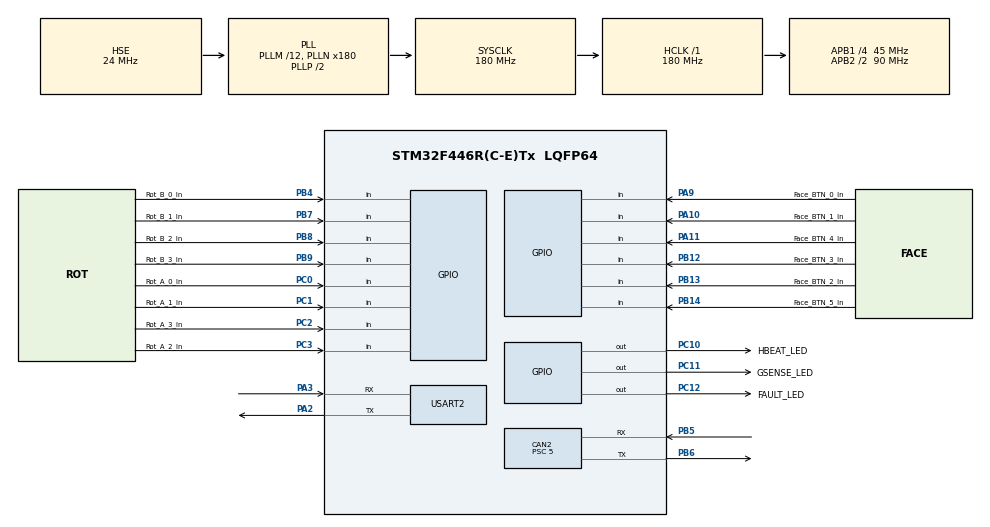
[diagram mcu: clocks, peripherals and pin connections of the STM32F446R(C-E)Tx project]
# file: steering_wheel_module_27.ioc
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CAN2.BS1=CAN_BS1_6TQ
CAN2.BS2=CAN_BS2_1TQ
CAN2.CalculateBaudRate=1125000
CAN2.CalculateTimeBit=888
CAN2.CalculateTimeQuantum=111.11111111111111
CAN2.Prescaler=5
FREERTOS.Tasks01=mainLoop,0,1024,main_task,Default,NULL,Dynamic,NULL,NULL;gcanBuffTask,0,1024,gcan_buffer_task,Default,NULL,Dynamic,NULL,NULL
FREERTOS.configENABLE_FPU=1
Mcu.Family=STM32F4
Mcu.Name=STM32F446R(C-E)Tx
Mcu.Package=LQFP64
NVIC.PriorityGroup=NVIC_PRIORITYGROUP_4
NVIC.TIM1_UP_TIM10_IRQn=true\:5\:0\:false\:false\:true\:true\:true\:true\:true
NVIC.TIM6_DAC_IRQn=true\:15\:0\:false\:false\:true\:false\:false\:true\:true
NVIC.TimeBase=TIM6_DAC_IRQn
NVIC.TimeBaseIP=TIM6
PA10.GPIO_Label=Face_BTN_1_In
PA10.Signal=GPIO_Input
PA11.GPIO_Label=Face_BTN_4_In
PA11.Signal=GPIO_Input
PA13.Signal=SYS_JTMS-SWDIO
PA14.Signal=SYS_JTCK-SWCLK
PA2.Mode=Asynchronous
PA2.Signal=USART2_TX
PA3.Mode=Asynchronous
PA3.Signal=USART2_RX
PA9.GPIO_Label=Face_BTN_0_In
PA9.Signal=GPIO_Input
PB12.GPIO_Label=Face_BTN_3_In
PB12.Signal=GPIO_Input
PB13.GPIO_Label=Face_BTN_2_In
PB13.Signal=GPIO_Input
PB14.GPIO_Label=Face_BTN_5_In
PB14.Signal=GPIO_Input
PB3.Signal=SYS_JTDO-SWO
PB4.GPIO_Label=Rot_B_0_In
PB4.Signal=GPIO_Input
PB5.Mode=CAN_Activate
PB5.Signal=CAN2_RX
PB6.Mode=CAN_Activate
PB6.Signal=CAN2_TX
PB7.GPIO_Label=Rot_B_1_In
PB7.Signal=GPIO_Input
PB8.GPIO_Label=Rot_B_2_In
PB8.Signal=GPIO_Input
PB9.GPIO_Label=Rot_B_3_In
PB9.Signal=GPIO_Input
PC0.GPIO_Label=Rot_A_0_In
PC0.Signal=GPIO_Input
PC1.GPIO_Label=Rot_A_1_In
PC1.Signal=GPIO_Input
PC10.GPIO_Label=HBEAT_LED
PC10.Signal=GPIO_Output
PC11.GPIO_Label=GSENSE_LED
PC11.Signal=GPIO_Output
PC12.GPIO_Label=FAULT_LED
PC12.Signal=GPIO_Output
PC2.GPIO_Label=Rot_A_3_In
PC2.Signal=GPIO_Input
PC3.GPIO_Label=Rot_A_2_In
PC3.Signal=GPIO_Input
PH0-OSC_IN.Mode=HSE-External-Clock-Source
PH0-OSC_IN.Signal=RCC_OSC_IN
PH1-OSC_OUT.Mode=HSE-External-Clock-Source
PH1-OSC_OUT.Signal=RCC_OSC_OUT
ProjectManager.HeapSize=0x200
ProjectManager.StackSize=0x400
ProjectManager.TargetToolchain=STM32CubeIDE
RCC.AHBFreq_Value=180000000
RCC.APB1CLKDivider=RCC_HCLK_DIV4
RCC.APB1Freq_Value=45000000
RCC.APB1TimFreq_Value=90000000
RCC.APB2CLKDivider=RCC_HCLK_DIV2
RCC.APB2Freq_Value=90000000
RCC.APB2TimFreq_Value=180000000
RCC.CortexFreq_Value=180000000
RCC.HCLKFreq_Value=180000000
RCC.HSE_VALUE=24000000
RCC.PLLM=12
RCC.PLLN=180
RCC.PLLSourceVirtual=RCC_PLLSOURCE_HSE
RCC.SYSCLKFreq_VALUE=180000000
RCC.SYSCLKSource=RCC_SYSCLKSOURCE_PLLCLK
RCC.USBFreq_Value=180000000
RCC.VCOOutputFreq_Value=360000000
USART2.VirtualMode=VM_ASYNC
VP_FREERTOS_VS_CMSIS_V1.Mode=CMSIS_V1
VP_SYS_VS_tim6.Mode=TIM6
VP_TIM10_VS_ClockSourceINT.Mode=Enable_Timer
board=custom

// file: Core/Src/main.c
/* USER CODE BEGIN Header */
/**
  ******************************************************************************
  * @file           : main.c
  * @brief          : Main program body
  ******************************************************************************
  * @attention
  *
  * Copyright (c) 2025 STMicroelectronics.
  * All rights reserved.
  *
  * This software is licensed under terms that can be found in the LICENSE file
  * in the root directory of this software component.
  * If no LICENSE file comes with this software, it is provided AS-IS.
  *
  ******************************************************************************
  */
/* USER CODE END Header */
#include "main.h"
#include "cmsis_os.h"

/* USER CODE BEGIN Includes */
#include "GopherCAN.h"
#include "steering_wheel_module.h"
#include "gopher_sense.h"
/* USER CODE END Includes */

CAN_HandleTypeDef hcan2;

TIM_HandleTypeDef htim10;

UART_HandleTypeDef huart2;

osThreadId mainLoopHandle;
osThreadId gcanBuffTaskHandle;

void SystemClock_Config(void);
static void MX_GPIO_Init(void);
static void MX_CAN2_Init(void);
static void MX_TIM10_Init(void);
static void MX_USART2_UART_Init(void);
void main_task(void const * argument);
void gcan_buffer_task(void const * argument);

int main(void)
{

  /* MCU Configuration--------------------------------------------------------*/

  /* Reset of all peripherals, Initializes the Flash interface and the Systick. */
  HAL_Init();

  /* Configure the system clock */
  SystemClock_Config();

  /* Initialize all configured peripherals */
  MX_GPIO_Init();
  MX_CAN2_Init();
  MX_TIM10_Init();
  MX_USART2_UART_Init();
  /* USER CODE BEGIN 2 */
  init(&hcan2, &huart2);
  gsense_init(&hcan2, GSENSE_LED_GPIO_Port, GSENSE_LED_Pin);
  /* USER CODE END 2 */

  /* Create the thread(s) */
  /* definition and creation of mainLoop */
  osThreadDef(mainLoop, main_task, osPriorityNormal, 0, 1024);
  mainLoopHandle = osThreadCreate(osThread(mainLoop), NULL);

  /* definition and creation of gcanBuffTask */
  osThreadDef(gcanBuffTask, gcan_buffer_task, osPriorityNormal, 0, 1024);
  gcanBuffTaskHandle = osThreadCreate(osThread(gcanBuffTask), NULL);

  /* Start scheduler */
  osKernelStart();

  /* We should never get here as control is now taken by the scheduler */

  /* Infinite loop */
  while (1)
  {

  }
}

void SystemClock_Config(void)
{
  RCC_OscInitTypeDef RCC_OscInitStruct = {0};
  RCC_ClkInitTypeDef RCC_ClkInitStruct = {0};

  /** Configure the main internal regulator output voltage
  */
  __HAL_RCC_PWR_CLK_ENABLE();
  __HAL_PWR_VOLTAGESCALING_CONFIG(PWR_REGULATOR_VOLTAGE_SCALE1);

  /** Initializes the RCC Oscillators according to the specified parameters
  * in the RCC_OscInitTypeDef structure.
  */
  RCC_OscInitStruct.OscillatorType = RCC_OSCILLATORTYPE_HSE;
  RCC_OscInitStruct.HSEState = RCC_HSE_BYPASS;
  RCC_OscInitStruct.PLL.PLLState = RCC_PLL_ON;
  RCC_OscInitStruct.PLL.PLLSource = RCC_PLLSOURCE_HSE;
  RCC_OscInitStruct.PLL.PLLM = 12;
  RCC_OscInitStruct.PLL.PLLN = 180;
  RCC_OscInitStruct.PLL.PLLP = RCC_PLLP_DIV2;
  RCC_OscInitStruct.PLL.PLLQ = 2;
  RCC_OscInitStruct.PLL.PLLR = 2;
  if (HAL_RCC_OscConfig(&RCC_OscInitStruct) != HAL_OK)
  {
    Error_Handler();
  }

  /** Activate the Over-Drive mode
  */
  if (HAL_PWREx_EnableOverDrive() != HAL_OK)
  {
    Error_Handler();
  }

  /** Initializes the CPU, AHB and APB buses clocks
  */
  RCC_ClkInitStruct.ClockType = RCC_CLOCKTYPE_HCLK|RCC_CLOCKTYPE_SYSCLK
                              |RCC_CLOCKTYPE_PCLK1|RCC_CLOCKTYPE_PCLK2;
  RCC_ClkInitStruct.SYSCLKSource = RCC_SYSCLKSOURCE_PLLCLK;
  RCC_ClkInitStruct.AHBCLKDivider = RCC_SYSCLK_DIV1;
  RCC_ClkInitStruct.APB1CLKDivider = RCC_HCLK_DIV4;
  RCC_ClkInitStruct.APB2CLKDivider = RCC_HCLK_DIV2;

  if (HAL_RCC_ClockConfig(&RCC_ClkInitStruct, FLASH_LATENCY_5) != HAL_OK)
  {
    Error_Handler();
  }
}

static void MX_CAN2_Init(void)
{

  hcan2.Instance = CAN2;
  hcan2.Init.Prescaler = 5;
  hcan2.Init.Mode = CAN_MODE_NORMAL;
  hcan2.Init.SyncJumpWidth = CAN_SJW_1TQ;
  hcan2.Init.TimeSeg1 = CAN_BS1_6TQ;
  hcan2.Init.TimeSeg2 = CAN_BS2_1TQ;
  hcan2.Init.TimeTriggeredMode = DISABLE;
  hcan2.Init.AutoBusOff = DISABLE;
  hcan2.Init.AutoWakeUp = DISABLE;
  hcan2.Init.AutoRetransmission = DISABLE;
  hcan2.Init.ReceiveFifoLocked = DISABLE;
  hcan2.Init.TransmitFifoPriority = DISABLE;
  if (HAL_CAN_Init(&hcan2) != HAL_OK)
  {
    Error_Handler();
  }

}

static void MX_TIM10_Init(void)
{

  htim10.Instance = TIM10;
  htim10.Init.Prescaler = 0;
  htim10.Init.CounterMode = TIM_COUNTERMODE_UP;
  htim10.Init.Period = 65535;
  htim10.Init.ClockDivision = TIM_CLOCKDIVISION_DIV1;
  htim10.Init.AutoReloadPreload = TIM_AUTORELOAD_PRELOAD_DISABLE;
  if (HAL_TIM_Base_Init(&htim10) != HAL_OK)
  {
    Error_Handler();
  }

}

static void MX_USART2_UART_Init(void)
{

  huart2.Instance = USART2;
  huart2.Init.BaudRate = 115200;
  huart2.Init.WordLength = UART_WORDLENGTH_8B;
  huart2.Init.StopBits = UART_STOPBITS_1;
  huart2.Init.Parity = UART_PARITY_NONE;
  huart2.Init.Mode = UART_MODE_TX_RX;
  huart2.Init.HwFlowCtl = UART_HWCONTROL_NONE;
  huart2.Init.OverSampling = UART_OVERSAMPLING_16;
  if (HAL_UART_Init(&huart2) != HAL_OK)
  {
    Error_Handler();
  }

}

static void MX_GPIO_Init(void)
{
  GPIO_InitTypeDef GPIO_InitStruct = {0};

  /* GPIO Ports Clock Enable */
  __HAL_RCC_GPIOH_CLK_ENABLE();
  __HAL_RCC_GPIOC_CLK_ENABLE();
  __HAL_RCC_GPIOA_CLK_ENABLE();
  __HAL_RCC_GPIOB_CLK_ENABLE();

  /*Configure GPIO pin Output Level */
  HAL_GPIO_WritePin(GPIOC, HBEAT_LED_Pin|GSENSE_LED_Pin|FAULT_LED_Pin, GPIO_PIN_RESET);

  /*Configure GPIO pins : Rot_A_0_In_Pin Rot_A_1_In_Pin Rot_A_3_In_Pin Rot_A_2_In_Pin */
  GPIO_InitStruct.Pin = Rot_A_0_In_Pin|Rot_A_1_In_Pin|Rot_A_3_In_Pin|Rot_A_2_In_Pin;
  GPIO_InitStruct.Mode = GPIO_MODE_INPUT;
  GPIO_InitStruct.Pull = GPIO_NOPULL;
  HAL_GPIO_Init(GPIOC, &GPIO_InitStruct);

  /*Configure GPIO pins : Face_BTN_3_In_Pin Face_BTN_2_In_Pin Face_BTN_5_In_Pin Rot_B_0_In_Pin
                           Rot_B_1_In_Pin Rot_B_2_In_Pin Rot_B_3_In_Pin */
  GPIO_InitStruct.Pin = Face_BTN_3_In_Pin|Face_BTN_2_In_Pin|Face_BTN_5_In_Pin|Rot_B_0_In_Pin
                          |Rot_B_1_In_Pin|Rot_B_2_In_Pin|Rot_B_3_In_Pin;
  GPIO_InitStruct.Mode = GPIO_MODE_INPUT;
  GPIO_InitStruct.Pull = GPIO_NOPULL;
  HAL_GPIO_Init(GPIOB, &GPIO_InitStruct);

  /*Configure GPIO pins : Face_BTN_0_In_Pin Face_BTN_1_In_Pin Face_BTN_4_In_Pin */
  GPIO_InitStruct.Pin = Face_BTN_0_In_Pin|Face_BTN_1_In_Pin|Face_BTN_4_In_Pin;
  GPIO_InitStruct.Mode = GPIO_MODE_INPUT;
  GPIO_InitStruct.Pull = GPIO_NOPULL;
  HAL_GPIO_Init(GPIOA, &GPIO_InitStruct);

  /*Configure GPIO pins : HBEAT_LED_Pin GSENSE_LED_Pin FAULT_LED_Pin */
  GPIO_InitStruct.Pin = HBEAT_LED_Pin|GSENSE_LED_Pin|FAULT_LED_Pin;
  GPIO_InitStruct.Mode = GPIO_MODE_OUTPUT_PP;
  GPIO_InitStruct.Pull = GPIO_NOPULL;
  GPIO_InitStruct.Speed = GPIO_SPEED_FREQ_LOW;
  HAL_GPIO_Init(GPIOC, &GPIO_InitStruct);

}

void main_task(void const * argument)
{
  /* USER CODE BEGIN 5 */
  /* Infinite loop */
  for(;;)
  {
    main_loop();
    osDelay(1);
  }
  /* USER CODE END 5 */
}

void gcan_buffer_task(void const * argument)
{
  /* USER CODE BEGIN gcan_buffer_task */
  /* Infinite loop */
  for(;;)
  {
    can_buffer_handling_loop();
    osDelay(1);
  }
  /* USER CODE END gcan_buffer_task */
}

void HAL_TIM_PeriodElapsedCallback(TIM_HandleTypeDef *htim)
{
  if (htim->Instance == TIM6)
  {
    HAL_IncTick();
  }
}

void Error_Handler(void)
{
  __disable_irq();
  while (1)
  {
  }
}
